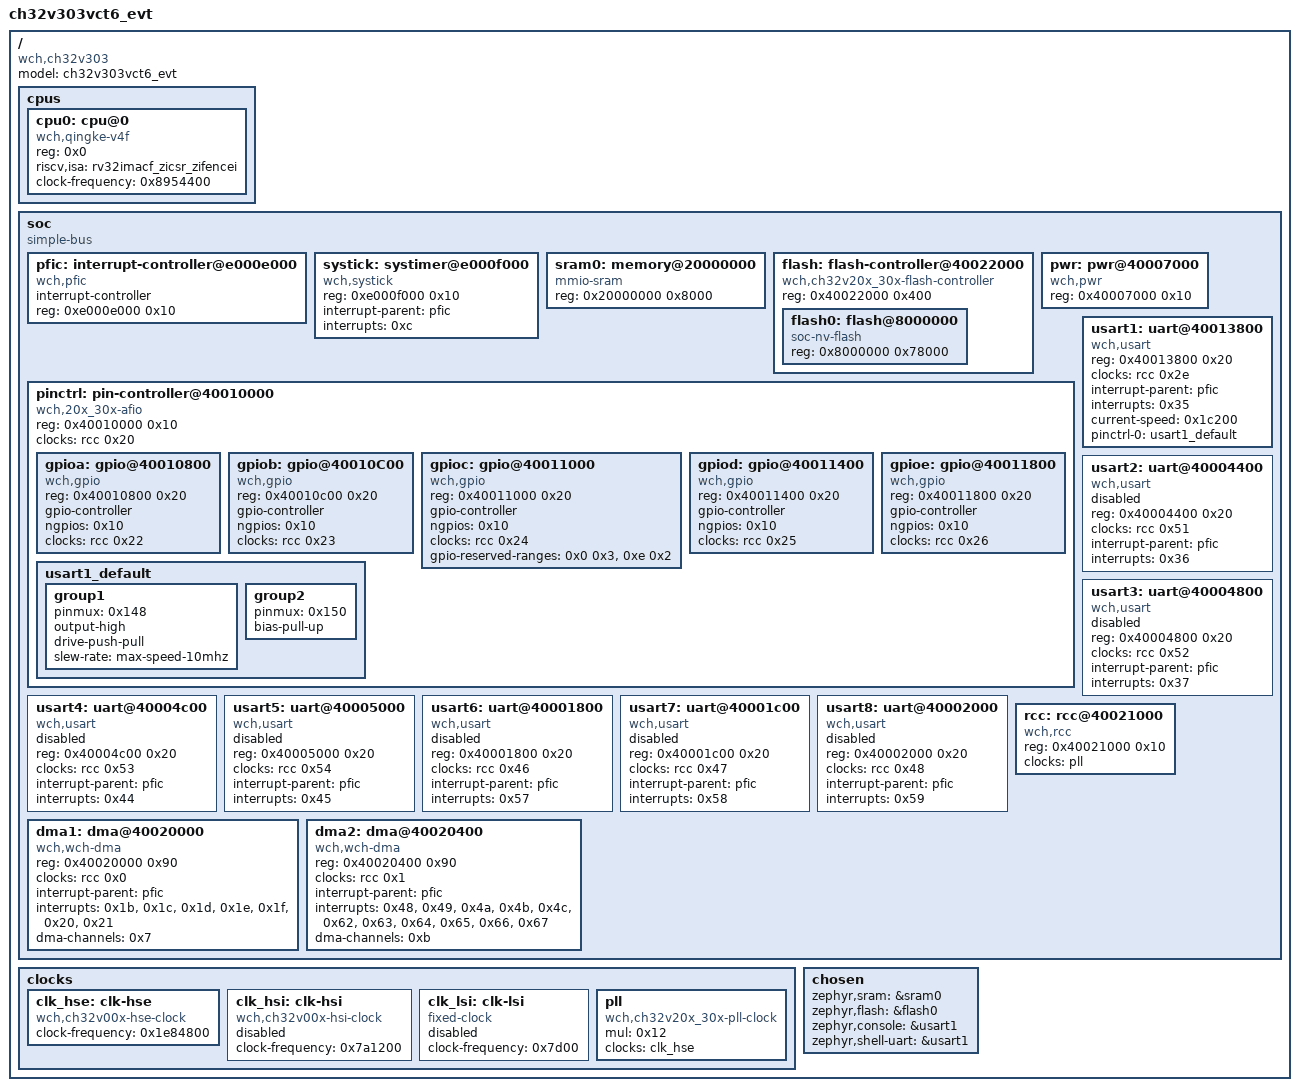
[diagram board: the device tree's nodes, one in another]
/dts-v1/;

/* node '/' defined in zephyr/dts/riscv/wch/qingke-v4f.dtsi:7 */
/ {
	#address-cells = < 0x1 >;    /* in zephyr/dts/riscv/wch/qingke-v4f.dtsi:8 */
	#size-cells = < 0x1 >;       /* in zephyr/dts/riscv/wch/qingke-v4f.dtsi:9 */
	model = "ch32v303vct6_evt";  /* in zephyr/boards/wch/ch32v303vct6_evt/ch32v303vct6_evt.dts:14 */
	compatible = "wch,ch32v303"; /* in zephyr/boards/wch/ch32v303vct6_evt/ch32v303vct6_evt.dts:15 */

	/* node '/cpus' defined in zephyr/dts/riscv/wch/qingke-v4f.dtsi:11 */
	cpus {
		#address-cells = < 0x1 >; /* in zephyr/dts/riscv/wch/qingke-v4f.dtsi:12 */
		#size-cells = < 0x0 >;    /* in zephyr/dts/riscv/wch/qingke-v4f.dtsi:13 */

		/* node '/cpus/cpu@0' defined in zephyr/dts/riscv/wch/qingke-v4f.dtsi:15 */
		cpu0: cpu@0 {
			device_type = "cpu";                    /* in zephyr/dts/riscv/wch/qingke-v4f.dtsi:16 */
			compatible = "wch,qingke-v4f";          /* in zephyr/dts/riscv/wch/qingke-v4f.dtsi:17 */
			reg = < 0x0 >;                          /* in zephyr/dts/riscv/wch/qingke-v4f.dtsi:18 */
			riscv,isa = "rv32imacf_zicsr_zifencei"; /* in zephyr/dts/riscv/wch/qingke-v4f.dtsi:19 */
			clock-frequency = < 0x8954400 >;        /* in zephyr/dts/riscv/wch/ch32v303/ch32v303.dtsi:225 */
		};
	};

	/* node '/soc' defined in zephyr/dts/riscv/wch/qingke-v4f.dtsi:23 */
	soc {
		#address-cells = < 0x1 >;  /* in zephyr/dts/riscv/wch/qingke-v4f.dtsi:24 */
		#size-cells = < 0x1 >;     /* in zephyr/dts/riscv/wch/qingke-v4f.dtsi:25 */
		compatible = "simple-bus"; /* in zephyr/dts/riscv/wch/qingke-v4f.dtsi:26 */
		ranges;                    /* in zephyr/dts/riscv/wch/qingke-v4f.dtsi:27 */

		/* node '/soc/interrupt-controller@e000e000' defined in zephyr/dts/riscv/wch/qingke-v4f.dtsi:29 */
		pfic: interrupt-controller@e000e000 {
			compatible = "wch,pfic";    /* in zephyr/dts/riscv/wch/qingke-v4f.dtsi:30 */
			#address-cells = < 0x0 >;   /* in zephyr/dts/riscv/wch/qingke-v4f.dtsi:31 */
			#interrupt-cells = < 0x1 >; /* in zephyr/dts/riscv/wch/qingke-v4f.dtsi:32 */
			interrupt-controller;       /* in zephyr/dts/riscv/wch/qingke-v4f.dtsi:33 */
			reg = < 0xe000e000 0x10 >;  /* in zephyr/dts/riscv/wch/qingke-v4f.dtsi:34 */
			status = "okay";            /* in zephyr/dts/riscv/wch/qingke-v4f.dtsi:35 */
			phandle = < 0x1 >;          /* in zephyr/dts/riscv/wch/qingke-v4f.dtsi:42 */
		};

		/* node '/soc/systimer@e000f000' defined in zephyr/dts/riscv/wch/qingke-v4f.dtsi:38 */
		systick: systimer@e000f000 {
			compatible = "wch,systick";   /* in zephyr/dts/riscv/wch/qingke-v4f.dtsi:39 */
			reg = < 0xe000f000 0x10 >;    /* in zephyr/dts/riscv/wch/qingke-v4f.dtsi:40 */
			status = "okay";              /* in zephyr/dts/riscv/wch/qingke-v4f.dtsi:41 */
			interrupt-parent = < &pfic >; /* in zephyr/dts/riscv/wch/qingke-v4f.dtsi:42 */
			interrupts = < 0xc >;         /* in zephyr/dts/riscv/wch/qingke-v4f.dtsi:43 */
		};

		/* node '/soc/memory@20000000' defined in zephyr/dts/riscv/wch/ch32v303/ch32v303.dtsi:46 */
		sram0: memory@20000000 {
			compatible = "mmio-sram";    /* in zephyr/dts/riscv/wch/ch32v303/ch32v303.dtsi:47 */
			reg = < 0x20000000 0x8000 >; /* in zephyr/dts/riscv/wch/ch32v303/ch32v303.dtsi:48 */
		};

		/* node '/soc/flash-controller@40022000' defined in zephyr/dts/riscv/wch/ch32v303/ch32v303.dtsi:51 */
		flash: flash-controller@40022000 {
			compatible = "wch,ch32v20x_30x-flash-controller"; /* in zephyr/dts/riscv/wch/ch32v303/ch32v303.dtsi:52 */
			reg = < 0x40022000 0x400 >;                       /* in zephyr/dts/riscv/wch/ch32v303/ch32v303.dtsi:53 */
			#address-cells = < 0x1 >;                         /* in zephyr/dts/riscv/wch/ch32v303/ch32v303.dtsi:55 */
			#size-cells = < 0x1 >;                            /* in zephyr/dts/riscv/wch/ch32v303/ch32v303.dtsi:56 */

			/* node '/soc/flash-controller@40022000/flash@8000000' defined in zephyr/dts/riscv/wch/ch32v303/ch32v303.dtsi:58 */
			flash0: flash@8000000 {
				compatible = "soc-nv-flash"; /* in zephyr/dts/riscv/wch/ch32v303/ch32v303.dtsi:59 */
				reg = < 0x8000000 0x78000 >; /* in zephyr/dts/riscv/wch/ch32v303/ch32v303.dtsi:60 */
			};
		};

		/* node '/soc/pwr@40007000' defined in zephyr/dts/riscv/wch/ch32v303/ch32v303.dtsi:64 */
		pwr: pwr@40007000 {
			compatible = "wch,pwr";    /* in zephyr/dts/riscv/wch/ch32v303/ch32v303.dtsi:65 */
			reg = < 0x40007000 0x10 >; /* in zephyr/dts/riscv/wch/ch32v303/ch32v303.dtsi:66 */
		};

		/* node '/soc/pin-controller@40010000' defined in zephyr/dts/riscv/wch/ch32v303/ch32v303.dtsi:69 */
		pinctrl: pin-controller@40010000 {
			compatible = "wch,20x_30x-afio"; /* in zephyr/dts/riscv/wch/ch32v303/ch32v303.dtsi:70 */
			reg = < 0x40010000 0x10 >;       /* in zephyr/dts/riscv/wch/ch32v303/ch32v303.dtsi:71 */
			#address-cells = < 0x1 >;        /* in zephyr/dts/riscv/wch/ch32v303/ch32v303.dtsi:72 */
			#size-cells = < 0x1 >;           /* in zephyr/dts/riscv/wch/ch32v303/ch32v303.dtsi:73 */
			clocks = < &rcc 0x20 >;          /* in zephyr/dts/riscv/wch/ch32v303/ch32v303.dtsi:74 */

			/* node '/soc/pin-controller@40010000/gpio@40010800' defined in zephyr/dts/riscv/wch/ch32v303/ch32v303.dtsi:76 */
			gpioa: gpio@40010800 {
				compatible = "wch,gpio";   /* in zephyr/dts/riscv/wch/ch32v303/ch32v303.dtsi:77 */
				reg = < 0x40010800 0x20 >; /* in zephyr/dts/riscv/wch/ch32v303/ch32v303.dtsi:78 */
				gpio-controller;           /* in zephyr/dts/riscv/wch/ch32v303/ch32v303.dtsi:79 */
				#gpio-cells = < 0x2 >;     /* in zephyr/dts/riscv/wch/ch32v303/ch32v303.dtsi:80 */
				ngpios = < 0x10 >;         /* in zephyr/dts/riscv/wch/ch32v303/ch32v303.dtsi:81 */
				clocks = < &rcc 0x22 >;    /* in zephyr/dts/riscv/wch/ch32v303/ch32v303.dtsi:82 */
				status = "okay";           /* in zephyr/boards/wch/ch32v303vct6_evt/ch32v303vct6_evt.dts:40 */
			};

			/* node '/soc/pin-controller@40010000/gpio@40010C00' defined in zephyr/dts/riscv/wch/ch32v303/ch32v303.dtsi:85 */
			gpiob: gpio@40010C00 {
				compatible = "wch,gpio";   /* in zephyr/dts/riscv/wch/ch32v303/ch32v303.dtsi:86 */
				reg = < 0x40010c00 0x20 >; /* in zephyr/dts/riscv/wch/ch32v303/ch32v303.dtsi:87 */
				gpio-controller;           /* in zephyr/dts/riscv/wch/ch32v303/ch32v303.dtsi:88 */
				#gpio-cells = < 0x2 >;     /* in zephyr/dts/riscv/wch/ch32v303/ch32v303.dtsi:89 */
				ngpios = < 0x10 >;         /* in zephyr/dts/riscv/wch/ch32v303/ch32v303.dtsi:90 */
				clocks = < &rcc 0x23 >;    /* in zephyr/dts/riscv/wch/ch32v303/ch32v303.dtsi:91 */
			};

			/* node '/soc/pin-controller@40010000/gpio@40011000' defined in zephyr/dts/riscv/wch/ch32v303/ch32v303.dtsi:94 */
			gpioc: gpio@40011000 {
				compatible = "wch,gpio";            /* in zephyr/dts/riscv/wch/ch32v303/ch32v303.dtsi:95 */
				reg = < 0x40011000 0x20 >;          /* in zephyr/dts/riscv/wch/ch32v303/ch32v303.dtsi:96 */
				gpio-controller;                    /* in zephyr/dts/riscv/wch/ch32v303/ch32v303.dtsi:97 */
				#gpio-cells = < 0x2 >;              /* in zephyr/dts/riscv/wch/ch32v303/ch32v303.dtsi:98 */
				ngpios = < 0x10 >;                  /* in zephyr/dts/riscv/wch/ch32v303/ch32v303.dtsi:99 */
				clocks = < &rcc 0x24 >;             /* in zephyr/dts/riscv/wch/ch32v303/ch32v303.dtsi:100 */
				gpio-reserved-ranges = < 0x0 0x3 >,
				                       < 0xe 0x2 >; /* in zephyr/dts/riscv/wch/ch32v303/ch32v303vct.dtsi:10 */
				status = "okay";                    /* in zephyr/boards/wch/ch32v303vct6_evt/ch32v303vct6_evt.dts:44 */
			};

			/* node '/soc/pin-controller@40010000/gpio@40011400' defined in zephyr/dts/riscv/wch/ch32v303/ch32v303.dtsi:103 */
			gpiod: gpio@40011400 {
				compatible = "wch,gpio";   /* in zephyr/dts/riscv/wch/ch32v303/ch32v303.dtsi:104 */
				reg = < 0x40011400 0x20 >; /* in zephyr/dts/riscv/wch/ch32v303/ch32v303.dtsi:105 */
				gpio-controller;           /* in zephyr/dts/riscv/wch/ch32v303/ch32v303.dtsi:106 */
				#gpio-cells = < 0x2 >;     /* in zephyr/dts/riscv/wch/ch32v303/ch32v303.dtsi:107 */
				ngpios = < 0x10 >;         /* in zephyr/dts/riscv/wch/ch32v303/ch32v303.dtsi:108 */
				clocks = < &rcc 0x25 >;    /* in zephyr/dts/riscv/wch/ch32v303/ch32v303.dtsi:109 */
			};

			/* node '/soc/pin-controller@40010000/gpio@40011800' defined in zephyr/dts/riscv/wch/ch32v303/ch32v303.dtsi:112 */
			gpioe: gpio@40011800 {
				compatible = "wch,gpio";   /* in zephyr/dts/riscv/wch/ch32v303/ch32v303.dtsi:113 */
				reg = < 0x40011800 0x20 >; /* in zephyr/dts/riscv/wch/ch32v303/ch32v303.dtsi:114 */
				gpio-controller;           /* in zephyr/dts/riscv/wch/ch32v303/ch32v303.dtsi:115 */
				#gpio-cells = < 0x2 >;     /* in zephyr/dts/riscv/wch/ch32v303/ch32v303.dtsi:116 */
				ngpios = < 0x10 >;         /* in zephyr/dts/riscv/wch/ch32v303/ch32v303.dtsi:117 */
				clocks = < &rcc 0x26 >;    /* in zephyr/dts/riscv/wch/ch32v303/ch32v303.dtsi:118 */
			};

			/* node '/soc/pin-controller@40010000/usart1_default' defined in zephyr/boards/wch/ch32v303vct6_evt/ch32v303vct6_evt-pinctrl.dtsi:9 */
			usart1_default: usart1_default {
				phandle = < 0x3 >; /* in zephyr/boards/wch/ch32v303vct6_evt/ch32v303vct6_evt.dts:50 */

				/* node '/soc/pin-controller@40010000/usart1_default/group1' defined in zephyr/boards/wch/ch32v303vct6_evt/ch32v303vct6_evt-pinctrl.dtsi:10 */
				group1 {
					pinmux = < 0x148 >;            /* in zephyr/boards/wch/ch32v303vct6_evt/ch32v303vct6_evt-pinctrl.dtsi:11 */
					output-high;                   /* in zephyr/boards/wch/ch32v303vct6_evt/ch32v303vct6_evt-pinctrl.dtsi:12 */
					drive-push-pull;               /* in zephyr/boards/wch/ch32v303vct6_evt/ch32v303vct6_evt-pinctrl.dtsi:13 */
					slew-rate = "max-speed-10mhz"; /* in zephyr/boards/wch/ch32v303vct6_evt/ch32v303vct6_evt-pinctrl.dtsi:14 */
				};

				/* node '/soc/pin-controller@40010000/usart1_default/group2' defined in zephyr/boards/wch/ch32v303vct6_evt/ch32v303vct6_evt-pinctrl.dtsi:17 */
				group2 {
					pinmux = < 0x150 >; /* in zephyr/boards/wch/ch32v303vct6_evt/ch32v303vct6_evt-pinctrl.dtsi:18 */
					bias-pull-up;       /* in zephyr/boards/wch/ch32v303vct6_evt/ch32v303vct6_evt-pinctrl.dtsi:19 */
				};
			};
		};

		/* node '/soc/uart@40013800' defined in zephyr/dts/riscv/wch/ch32v303/ch32v303.dtsi:122 */
		usart1: uart@40013800 {
			compatible = "wch,usart";        /* in zephyr/dts/riscv/wch/ch32v303/ch32v303.dtsi:123 */
			reg = < 0x40013800 0x20 >;       /* in zephyr/dts/riscv/wch/ch32v303/ch32v303.dtsi:124 */
			clocks = < &rcc 0x2e >;          /* in zephyr/dts/riscv/wch/ch32v303/ch32v303.dtsi:125 */
			interrupt-parent = < &pfic >;    /* in zephyr/dts/riscv/wch/ch32v303/ch32v303.dtsi:126 */
			interrupts = < 0x35 >;           /* in zephyr/dts/riscv/wch/ch32v303/ch32v303.dtsi:127 */
			status = "okay";                 /* in zephyr/boards/wch/ch32v303vct6_evt/ch32v303vct6_evt.dts:48 */
			current-speed = < 0x1c200 >;     /* in zephyr/boards/wch/ch32v303vct6_evt/ch32v303vct6_evt.dts:49 */
			pinctrl-0 = < &usart1_default >; /* in zephyr/boards/wch/ch32v303vct6_evt/ch32v303vct6_evt.dts:50 */
			pinctrl-names = "default";       /* in zephyr/boards/wch/ch32v303vct6_evt/ch32v303vct6_evt.dts:51 */
		};

		/* node '/soc/uart@40004400' defined in zephyr/dts/riscv/wch/ch32v303/ch32v303.dtsi:131 */
		usart2: uart@40004400 {
			compatible = "wch,usart";     /* in zephyr/dts/riscv/wch/ch32v303/ch32v303.dtsi:132 */
			reg = < 0x40004400 0x20 >;    /* in zephyr/dts/riscv/wch/ch32v303/ch32v303.dtsi:133 */
			clocks = < &rcc 0x51 >;       /* in zephyr/dts/riscv/wch/ch32v303/ch32v303.dtsi:134 */
			interrupt-parent = < &pfic >; /* in zephyr/dts/riscv/wch/ch32v303/ch32v303.dtsi:135 */
			interrupts = < 0x36 >;        /* in zephyr/dts/riscv/wch/ch32v303/ch32v303.dtsi:136 */
			status = "disabled";          /* in zephyr/dts/riscv/wch/ch32v303/ch32v303.dtsi:137 */
		};

		/* node '/soc/uart@40004800' defined in zephyr/dts/riscv/wch/ch32v303/ch32v303.dtsi:140 */
		usart3: uart@40004800 {
			compatible = "wch,usart";     /* in zephyr/dts/riscv/wch/ch32v303/ch32v303.dtsi:141 */
			reg = < 0x40004800 0x20 >;    /* in zephyr/dts/riscv/wch/ch32v303/ch32v303.dtsi:142 */
			clocks = < &rcc 0x52 >;       /* in zephyr/dts/riscv/wch/ch32v303/ch32v303.dtsi:143 */
			interrupt-parent = < &pfic >; /* in zephyr/dts/riscv/wch/ch32v303/ch32v303.dtsi:144 */
			interrupts = < 0x37 >;        /* in zephyr/dts/riscv/wch/ch32v303/ch32v303.dtsi:145 */
			status = "disabled";          /* in zephyr/dts/riscv/wch/ch32v303/ch32v303.dtsi:146 */
		};

		/* node '/soc/uart@40004c00' defined in zephyr/dts/riscv/wch/ch32v303/ch32v303.dtsi:149 */
		usart4: uart@40004c00 {
			compatible = "wch,usart";     /* in zephyr/dts/riscv/wch/ch32v303/ch32v303.dtsi:150 */
			reg = < 0x40004c00 0x20 >;    /* in zephyr/dts/riscv/wch/ch32v303/ch32v303.dtsi:151 */
			clocks = < &rcc 0x53 >;       /* in zephyr/dts/riscv/wch/ch32v303/ch32v303.dtsi:152 */
			interrupt-parent = < &pfic >; /* in zephyr/dts/riscv/wch/ch32v303/ch32v303.dtsi:153 */
			interrupts = < 0x44 >;        /* in zephyr/dts/riscv/wch/ch32v303/ch32v303.dtsi:154 */
			status = "disabled";          /* in zephyr/dts/riscv/wch/ch32v303/ch32v303.dtsi:155 */
		};

		/* node '/soc/uart@40005000' defined in zephyr/dts/riscv/wch/ch32v303/ch32v303.dtsi:158 */
		usart5: uart@40005000 {
			compatible = "wch,usart";     /* in zephyr/dts/riscv/wch/ch32v303/ch32v303.dtsi:159 */
			reg = < 0x40005000 0x20 >;    /* in zephyr/dts/riscv/wch/ch32v303/ch32v303.dtsi:160 */
			clocks = < &rcc 0x54 >;       /* in zephyr/dts/riscv/wch/ch32v303/ch32v303.dtsi:161 */
			interrupt-parent = < &pfic >; /* in zephyr/dts/riscv/wch/ch32v303/ch32v303.dtsi:162 */
			interrupts = < 0x45 >;        /* in zephyr/dts/riscv/wch/ch32v303/ch32v303.dtsi:163 */
			status = "disabled";          /* in zephyr/dts/riscv/wch/ch32v303/ch32v303.dtsi:164 */
		};

		/* node '/soc/uart@40001800' defined in zephyr/dts/riscv/wch/ch32v303/ch32v303.dtsi:167 */
		usart6: uart@40001800 {
			compatible = "wch,usart";     /* in zephyr/dts/riscv/wch/ch32v303/ch32v303.dtsi:168 */
			reg = < 0x40001800 0x20 >;    /* in zephyr/dts/riscv/wch/ch32v303/ch32v303.dtsi:169 */
			clocks = < &rcc 0x46 >;       /* in zephyr/dts/riscv/wch/ch32v303/ch32v303.dtsi:170 */
			interrupt-parent = < &pfic >; /* in zephyr/dts/riscv/wch/ch32v303/ch32v303.dtsi:171 */
			interrupts = < 0x57 >;        /* in zephyr/dts/riscv/wch/ch32v303/ch32v303.dtsi:172 */
			status = "disabled";          /* in zephyr/dts/riscv/wch/ch32v303/ch32v303.dtsi:173 */
		};

		/* node '/soc/uart@40001c00' defined in zephyr/dts/riscv/wch/ch32v303/ch32v303.dtsi:176 */
		usart7: uart@40001c00 {
			compatible = "wch,usart";     /* in zephyr/dts/riscv/wch/ch32v303/ch32v303.dtsi:177 */
			reg = < 0x40001c00 0x20 >;    /* in zephyr/dts/riscv/wch/ch32v303/ch32v303.dtsi:178 */
			clocks = < &rcc 0x47 >;       /* in zephyr/dts/riscv/wch/ch32v303/ch32v303.dtsi:179 */
			interrupt-parent = < &pfic >; /* in zephyr/dts/riscv/wch/ch32v303/ch32v303.dtsi:180 */
			interrupts = < 0x58 >;        /* in zephyr/dts/riscv/wch/ch32v303/ch32v303.dtsi:181 */
			status = "disabled";          /* in zephyr/dts/riscv/wch/ch32v303/ch32v303.dtsi:182 */
		};

		/* node '/soc/uart@40002000' defined in zephyr/dts/riscv/wch/ch32v303/ch32v303.dtsi:185 */
		usart8: uart@40002000 {
			compatible = "wch,usart";     /* in zephyr/dts/riscv/wch/ch32v303/ch32v303.dtsi:186 */
			reg = < 0x40002000 0x20 >;    /* in zephyr/dts/riscv/wch/ch32v303/ch32v303.dtsi:187 */
			clocks = < &rcc 0x48 >;       /* in zephyr/dts/riscv/wch/ch32v303/ch32v303.dtsi:188 */
			interrupt-parent = < &pfic >; /* in zephyr/dts/riscv/wch/ch32v303/ch32v303.dtsi:189 */
			interrupts = < 0x59 >;        /* in zephyr/dts/riscv/wch/ch32v303/ch32v303.dtsi:190 */
			status = "disabled";          /* in zephyr/dts/riscv/wch/ch32v303/ch32v303.dtsi:191 */
		};

		/* node '/soc/rcc@40021000' defined in zephyr/dts/riscv/wch/ch32v303/ch32v303.dtsi:194 */
		rcc: rcc@40021000 {
			compatible = "wch,rcc";    /* in zephyr/dts/riscv/wch/ch32v303/ch32v303.dtsi:195 */
			reg = < 0x40021000 0x10 >; /* in zephyr/dts/riscv/wch/ch32v303/ch32v303.dtsi:196 */
			#clock-cells = < 0x1 >;    /* in zephyr/dts/riscv/wch/ch32v303/ch32v303.dtsi:197 */
			status = "okay";           /* in zephyr/dts/riscv/wch/ch32v303/ch32v303.dtsi:198 */
			clocks = < &pll >;         /* in zephyr/boards/wch/ch32v303vct6_evt/ch32v303vct6_evt.dts:36 */
			phandle = < 0x2 >;         /* in zephyr/dts/riscv/wch/ch32v303/ch32v303.dtsi:74 */
		};

		/* node '/soc/dma@40020000' defined in zephyr/dts/riscv/wch/ch32v303/ch32v303.dtsi:201 */
		dma1: dma@40020000 {
			compatible = "wch,wch-dma";   /* in zephyr/dts/riscv/wch/ch32v303/ch32v303.dtsi:202 */
			reg = < 0x40020000 0x90 >;    /* in zephyr/dts/riscv/wch/ch32v303/ch32v303.dtsi:203 */
			clocks = < &rcc 0x0 >;        /* in zephyr/dts/riscv/wch/ch32v303/ch32v303.dtsi:204 */
			#dma-cells = < 0x1 >;         /* in zephyr/dts/riscv/wch/ch32v303/ch32v303.dtsi:205 */
			interrupt-parent = < &pfic >; /* in zephyr/dts/riscv/wch/ch32v303/ch32v303.dtsi:206 */
			interrupts = < 0x1b >,
			             < 0x1c >,
			             < 0x1d >,
			             < 0x1e >,
			             < 0x1f >,
			             < 0x20 >,
			             < 0x21 >;        /* in zephyr/dts/riscv/wch/ch32v303/ch32v303.dtsi:207 */
			dma-channels = < 0x7 >;       /* in zephyr/dts/riscv/wch/ch32v303/ch32v303.dtsi:208 */
		};

		/* node '/soc/dma@40020400' defined in zephyr/dts/riscv/wch/ch32v303/ch32v303.dtsi:211 */
		dma2: dma@40020400 {
			compatible = "wch,wch-dma";   /* in zephyr/dts/riscv/wch/ch32v303/ch32v303.dtsi:212 */
			reg = < 0x40020400 0x90 >;    /* in zephyr/dts/riscv/wch/ch32v303/ch32v303.dtsi:213 */
			clocks = < &rcc 0x1 >;        /* in zephyr/dts/riscv/wch/ch32v303/ch32v303.dtsi:214 */
			#dma-cells = < 0x1 >;         /* in zephyr/dts/riscv/wch/ch32v303/ch32v303.dtsi:215 */
			interrupt-parent = < &pfic >; /* in zephyr/dts/riscv/wch/ch32v303/ch32v303.dtsi:216 */
			interrupts = < 0x48 >,
			             < 0x49 >,
			             < 0x4a >,
			             < 0x4b >,
			             < 0x4c >,
			             < 0x62 >,
			             < 0x63 >,
			             < 0x64 >,
			             < 0x65 >,
			             < 0x66 >,
			             < 0x67 >;        /* in zephyr/dts/riscv/wch/ch32v303/ch32v303.dtsi:217 */
			dma-channels = < 0xb >;       /* in zephyr/dts/riscv/wch/ch32v303/ch32v303.dtsi:219 */
		};
	};

	/* node '/clocks' defined in zephyr/dts/riscv/wch/ch32v303/ch32v303.dtsi:15 */
	clocks {

		/* node '/clocks/clk-hse' defined in zephyr/dts/riscv/wch/ch32v303/ch32v303.dtsi:16 */
		clk_hse: clk-hse {
			#clock-cells = < 0x0 >;                /* in zephyr/dts/riscv/wch/ch32v303/ch32v303.dtsi:17 */
			compatible = "wch,ch32v00x-hse-clock"; /* in zephyr/dts/riscv/wch/ch32v303/ch32v303.dtsi:18 */
			clock-frequency = < 0x1e84800 >;       /* in zephyr/boards/wch/ch32v303vct6_evt/ch32v303vct6_evt.dts:26 */
			status = "okay";                       /* in zephyr/boards/wch/ch32v303vct6_evt/ch32v303vct6_evt.dts:27 */
			phandle = < 0x5 >;                     /* in zephyr/boards/wch/ch32v303vct6_evt/ch32v303vct6_evt.dts:31 */
		};

		/* node '/clocks/clk-hsi' defined in zephyr/dts/riscv/wch/ch32v303/ch32v303.dtsi:23 */
		clk_hsi: clk-hsi {
			#clock-cells = < 0x0 >;                /* in zephyr/dts/riscv/wch/ch32v303/ch32v303.dtsi:24 */
			compatible = "wch,ch32v00x-hsi-clock"; /* in zephyr/dts/riscv/wch/ch32v303/ch32v303.dtsi:25 */
			clock-frequency = < 0x7a1200 >;        /* in zephyr/dts/riscv/wch/ch32v303/ch32v303.dtsi:26 */
			status = "disabled";                   /* in zephyr/dts/riscv/wch/ch32v303/ch32v303.dtsi:27 */
		};

		/* node '/clocks/clk-lsi' defined in zephyr/dts/riscv/wch/ch32v303/ch32v303.dtsi:30 */
		clk_lsi: clk-lsi {
			#clock-cells = < 0x0 >;       /* in zephyr/dts/riscv/wch/ch32v303/ch32v303.dtsi:31 */
			compatible = "fixed-clock";   /* in zephyr/dts/riscv/wch/ch32v303/ch32v303.dtsi:32 */
			clock-frequency = < 0x7d00 >; /* in zephyr/dts/riscv/wch/ch32v303/ch32v303.dtsi:33 */
			status = "disabled";          /* in zephyr/dts/riscv/wch/ch32v303/ch32v303.dtsi:34 */
		};

		/* node '/clocks/pll' defined in zephyr/dts/riscv/wch/ch32v303/ch32v303.dtsi:37 */
		pll: pll {
			#clock-cells = < 0x0 >;                    /* in zephyr/dts/riscv/wch/ch32v303/ch32v303.dtsi:38 */
			compatible = "wch,ch32v20x_30x-pll-clock"; /* in zephyr/dts/riscv/wch/ch32v303/ch32v303.dtsi:39 */
			mul = < 0x12 >;                            /* in zephyr/dts/riscv/wch/ch32v303/ch32v303.dtsi:40 */
			clocks = < &clk_hse >;                     /* in zephyr/boards/wch/ch32v303vct6_evt/ch32v303vct6_evt.dts:31 */
			status = "okay";                           /* in zephyr/boards/wch/ch32v303vct6_evt/ch32v303vct6_evt.dts:32 */
			phandle = < 0x4 >;                         /* in zephyr/boards/wch/ch32v303vct6_evt/ch32v303vct6_evt.dts:36 */
		};
	};

	/* node '/chosen' defined in zephyr/boards/wch/ch32v303vct6_evt/ch32v303vct6_evt.dts:17 */
	chosen {
		zephyr,sram = &sram0;        /* in zephyr/boards/wch/ch32v303vct6_evt/ch32v303vct6_evt.dts:18 */
		zephyr,flash = &flash0;      /* in zephyr/boards/wch/ch32v303vct6_evt/ch32v303vct6_evt.dts:19 */
		zephyr,console = &usart1;    /* in zephyr/boards/wch/ch32v303vct6_evt/ch32v303vct6_evt.dts:20 */
		zephyr,shell-uart = &usart1; /* in zephyr/boards/wch/ch32v303vct6_evt/ch32v303vct6_evt.dts:21 */
	};
};
